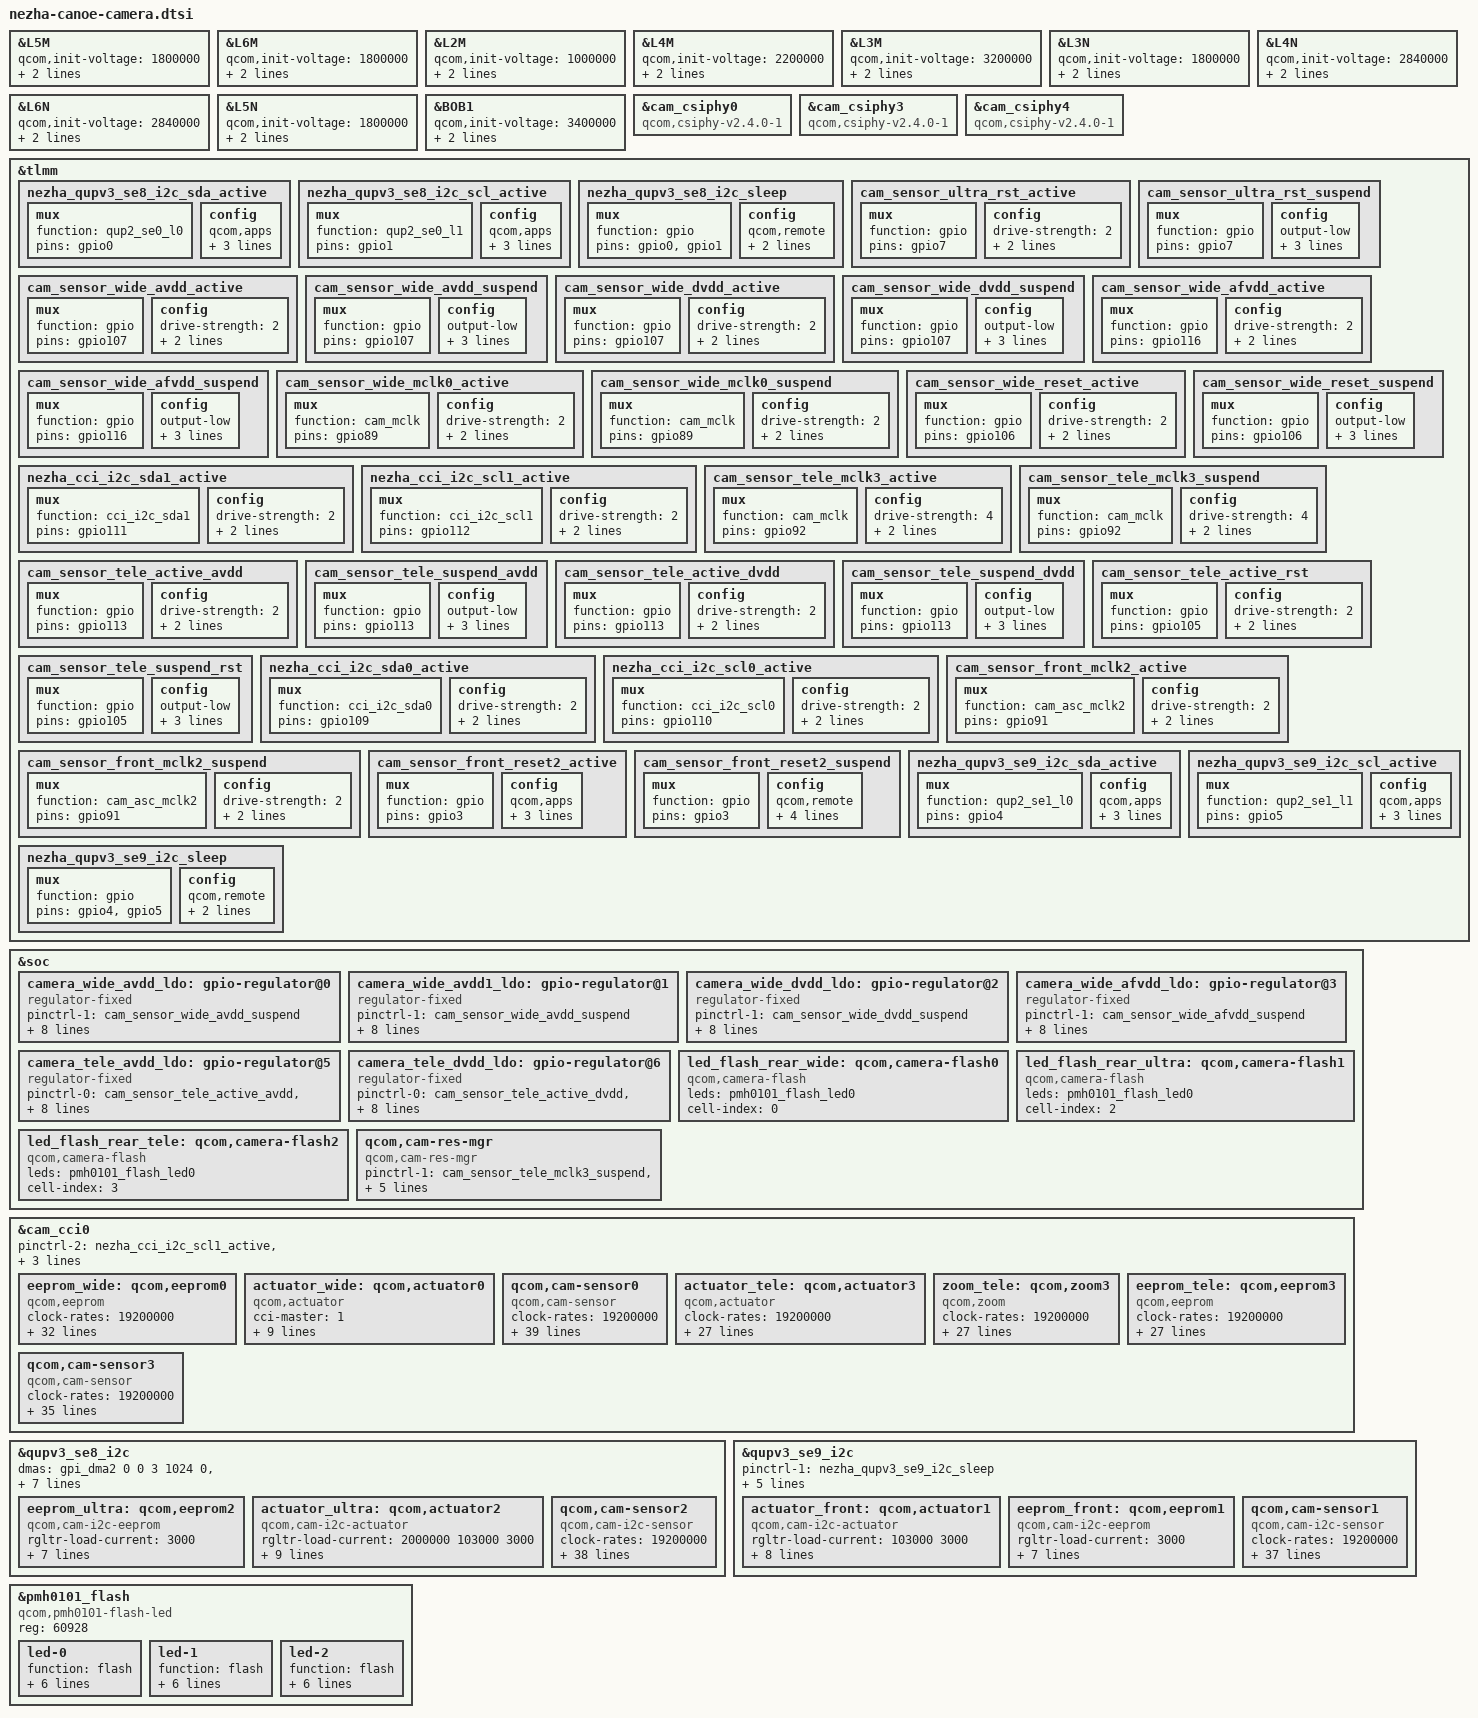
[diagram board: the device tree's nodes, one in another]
// SPDX-License-Identifier: GPL-2.0-only
/* Nezha OS4.0.7.0.XPACNXM board wiring, Canoe DTBO entry 1. */

&L5M {
	qcom,init-voltage = <1800000>;
	regulator-max-microvolt = <1800000>;
	regulator-min-microvolt = <1200000>;
};

&L6M {
	qcom,init-voltage = <1800000>;
	regulator-max-microvolt = <1800000>;
	regulator-min-microvolt = <1800000>;
};

&L2M {
	qcom,init-voltage = <1000000>;
	regulator-max-microvolt = <1000000>;
	regulator-min-microvolt = <1000000>;
};

&L4M {
	qcom,init-voltage = <2200000>;
	regulator-max-microvolt = <2200000>;
	regulator-min-microvolt = <2200000>;
};

&L3M {
	qcom,init-voltage = <3200000>;
	regulator-max-microvolt = <3200000>;
	regulator-min-microvolt = <3200000>;
};

&L3N {
	qcom,init-voltage = <1800000>;
	regulator-max-microvolt = <2800000>;
	regulator-min-microvolt = <1800000>;
};

&L4N {
	qcom,init-voltage = <2840000>;
	regulator-max-microvolt = <2840000>;
	regulator-min-microvolt = <2840000>;
};

&L6N {
	qcom,init-voltage = <2840000>;
	regulator-max-microvolt = <2840000>;
	regulator-min-microvolt = <2840000>;
};

&L5N {
	qcom,init-voltage = <1800000>;
	regulator-max-microvolt = <3304000>;
	regulator-min-microvolt = <1800000>;
};

&BOB1 {
	qcom,init-voltage = <3400000>;
	regulator-max-microvolt = <3400000>;
	regulator-min-microvolt = <3400000>;
};

&cam_csiphy0 {
	compatible = "qcom,csiphy-v2.4.0-1", "qcom,csiphy";
};

&cam_csiphy3 {
	compatible = "qcom,csiphy-v2.4.0-1", "qcom,csiphy";
};

&cam_csiphy4 {
	compatible = "qcom,csiphy-v2.4.0-1", "qcom,csiphy";
};

&tlmm {
	nezha_qupv3_se8_i2c_sda_active: nezha_qupv3_se8_i2c_sda_active {
		mux {
			function = "qup2_se0_l0";
			pins = "gpio0";
		};
		config {
			qcom,apps;
			bias-disable;
			drive-strength = <2>;
			pins = "gpio0";
		};
	};
	nezha_qupv3_se8_i2c_scl_active: nezha_qupv3_se8_i2c_scl_active {
		mux {
			function = "qup2_se0_l1";
			pins = "gpio1";
		};
		config {
			qcom,apps;
			bias-disable;
			drive-strength = <2>;
			pins = "gpio1";
		};
	};
	nezha_qupv3_se8_i2c_sleep: nezha_qupv3_se8_i2c_sleep {
		mux {
			function = "gpio";
			pins = "gpio0", "gpio1";
		};
		config {
			qcom,remote;
			drive-strength = <2>;
			pins = "gpio0", "gpio1";
		};
	};
	cam_sensor_ultra_rst_active: cam_sensor_ultra_rst_active {
		mux {
			function = "gpio";
			pins = "gpio7";
		};
		config {
			drive-strength = <2>;
			bias-disable;
			pins = "gpio7";
		};
	};
	cam_sensor_ultra_rst_suspend: cam_sensor_ultra_rst_suspend {
		mux {
			function = "gpio";
			pins = "gpio7";
		};
		config {
			output-low;
			drive-strength = <2>;
			bias-pull-down;
			pins = "gpio7";
		};
	};
	cam_sensor_wide_avdd_active: cam_sensor_wide_avdd_active {
		mux {
			function = "gpio";
			pins = "gpio107";
		};
		config {
			drive-strength = <2>;
			bias-disable;
			pins = "gpio107";
		};
	};
	cam_sensor_wide_avdd_suspend: cam_sensor_wide_avdd_suspend {
		mux {
			function = "gpio";
			pins = "gpio107";
		};
		config {
			output-low;
			drive-strength = <2>;
			bias-pull-down;
			pins = "gpio107";
		};
	};
	cam_sensor_wide_dvdd_active: cam_sensor_wide_dvdd_active {
		mux {
			function = "gpio";
			pins = "gpio107";
		};
		config {
			drive-strength = <2>;
			bias-disable;
			pins = "gpio107";
		};
	};
	cam_sensor_wide_dvdd_suspend: cam_sensor_wide_dvdd_suspend {
		mux {
			function = "gpio";
			pins = "gpio107";
		};
		config {
			output-low;
			drive-strength = <2>;
			bias-pull-down;
			pins = "gpio107";
		};
	};
	cam_sensor_wide_afvdd_active: cam_sensor_wide_afvdd_active {
		mux {
			function = "gpio";
			pins = "gpio116";
		};
		config {
			drive-strength = <2>;
			bias-disable;
			pins = "gpio116";
		};
	};
	cam_sensor_wide_afvdd_suspend: cam_sensor_wide_afvdd_suspend {
		mux {
			function = "gpio";
			pins = "gpio116";
		};
		config {
			output-low;
			drive-strength = <2>;
			bias-pull-down;
			pins = "gpio116";
		};
	};
	cam_sensor_wide_mclk0_active: cam_sensor_wide_mclk0_active {
		mux {
			function = "cam_mclk";
			pins = "gpio89";
		};
		config {
			drive-strength = <2>;
			bias-disable;
			pins = "gpio89";
		};
	};
	cam_sensor_wide_mclk0_suspend: cam_sensor_wide_mclk0_suspend {
		mux {
			function = "cam_mclk";
			pins = "gpio89";
		};
		config {
			drive-strength = <2>;
			bias-pull-down;
			pins = "gpio89";
		};
	};
	cam_sensor_wide_reset_active: cam_sensor_wide_reset_active {
		mux {
			function = "gpio";
			pins = "gpio106";
		};
		config {
			drive-strength = <2>;
			bias-disable;
			pins = "gpio106";
		};
	};
	cam_sensor_wide_reset_suspend: cam_sensor_wide_reset_suspend {
		mux {
			function = "gpio";
			pins = "gpio106";
		};
		config {
			output-low;
			drive-strength = <2>;
			bias-pull-down;
			pins = "gpio106";
		};
	};
	nezha_cci_i2c_sda1_active: nezha_cci_i2c_sda1_active {
		mux {
			function = "cci_i2c_sda1";
			pins = "gpio111";
		};
		config {
			drive-strength = <2>;
			bias-disable;
			pins = "gpio111";
		};
	};
	nezha_cci_i2c_scl1_active: nezha_cci_i2c_scl1_active {
		mux {
			function = "cci_i2c_scl1";
			pins = "gpio112";
		};
		config {
			drive-strength = <2>;
			bias-disable;
			pins = "gpio112";
		};
	};
	cam_sensor_tele_mclk3_active: cam_sensor_tele_mclk3_active {
		mux {
			function = "cam_mclk";
			pins = "gpio92";
		};
		config {
			drive-strength = <4>;
			bias-disable;
			pins = "gpio92";
		};
	};
	cam_sensor_tele_mclk3_suspend: cam_sensor_tele_mclk3_suspend {
		mux {
			function = "cam_mclk";
			pins = "gpio92";
		};
		config {
			drive-strength = <4>;
			bias-pull-down;
			pins = "gpio92";
		};
	};
	cam_sensor_tele_active_avdd: cam_sensor_tele_active_avdd {
		mux {
			function = "gpio";
			pins = "gpio113";
		};
		config {
			drive-strength = <2>;
			bias-disable;
			pins = "gpio113";
		};
	};
	cam_sensor_tele_suspend_avdd: cam_sensor_tele_suspend_avdd {
		mux {
			function = "gpio";
			pins = "gpio113";
		};
		config {
			output-low;
			drive-strength = <2>;
			bias-pull-down;
			pins = "gpio113";
		};
	};
	cam_sensor_tele_active_dvdd: cam_sensor_tele_active_dvdd {
		mux {
			function = "gpio";
			pins = "gpio113";
		};
		config {
			drive-strength = <2>;
			bias-disable;
			pins = "gpio113";
		};
	};
	cam_sensor_tele_suspend_dvdd: cam_sensor_tele_suspend_dvdd {
		mux {
			function = "gpio";
			pins = "gpio113";
		};
		config {
			output-low;
			drive-strength = <2>;
			bias-pull-down;
			pins = "gpio113";
		};
	};
	cam_sensor_tele_active_rst: cam_sensor_tele_active_rst {
		mux {
			function = "gpio";
			pins = "gpio105";
		};
		config {
			drive-strength = <2>;
			bias-disable;
			pins = "gpio105";
		};
	};
	cam_sensor_tele_suspend_rst: cam_sensor_tele_suspend_rst {
		mux {
			function = "gpio";
			pins = "gpio105";
		};
		config {
			output-low;
			drive-strength = <2>;
			bias-pull-down;
			pins = "gpio105";
		};
	};
	nezha_cci_i2c_sda0_active: nezha_cci_i2c_sda0_active {
		mux {
			function = "cci_i2c_sda0";
			pins = "gpio109";
		};
		config {
			drive-strength = <2>;
			bias-disable;
			pins = "gpio109";
		};
	};
	nezha_cci_i2c_scl0_active: nezha_cci_i2c_scl0_active {
		mux {
			function = "cci_i2c_scl0";
			pins = "gpio110";
		};
		config {
			drive-strength = <2>;
			bias-disable;
			pins = "gpio110";
		};
	};
	cam_sensor_front_mclk2_active: cam_sensor_front_mclk2_active {
		mux {
			function = "cam_asc_mclk2";
			pins = "gpio91";
		};
		config {
			drive-strength = <2>;
			bias-disable;
			pins = "gpio91";
		};
	};
	cam_sensor_front_mclk2_suspend: cam_sensor_front_mclk2_suspend {
		mux {
			function = "cam_asc_mclk2";
			pins = "gpio91";
		};
		config {
			drive-strength = <2>;
			bias-pull-down;
			pins = "gpio91";
		};
	};
	cam_sensor_front_reset2_active: cam_sensor_front_reset2_active {
		mux {
			function = "gpio";
			pins = "gpio3";
		};
		config {
			qcom,apps;
			drive-strength = <2>;
			bias-disable;
			pins = "gpio3";
		};
	};
	cam_sensor_front_reset2_suspend: cam_sensor_front_reset2_suspend {
		mux {
			function = "gpio";
			pins = "gpio3";
		};
		config {
			qcom,remote;
			output-low;
			drive-strength = <2>;
			bias-pull-down;
			pins = "gpio3";
		};
	};
	nezha_qupv3_se9_i2c_sda_active: nezha_qupv3_se9_i2c_sda_active {
		mux {
			function = "qup2_se1_l0";
			pins = "gpio4";
		};
		config {
			qcom,apps;
			bias-disable;
			drive-strength = <2>;
			pins = "gpio4";
		};
	};
	nezha_qupv3_se9_i2c_scl_active: nezha_qupv3_se9_i2c_scl_active {
		mux {
			function = "qup2_se1_l1";
			pins = "gpio5";
		};
		config {
			qcom,apps;
			bias-disable;
			drive-strength = <2>;
			pins = "gpio5";
		};
	};
	nezha_qupv3_se9_i2c_sleep: nezha_qupv3_se9_i2c_sleep {
		mux {
			function = "gpio";
			pins = "gpio4", "gpio5";
		};
		config {
			qcom,remote;
			drive-strength = <2>;
			pins = "gpio4", "gpio5";
		};
	};
};

&soc {
	camera_wide_avdd_ldo: gpio-regulator@0 {
		pinctrl-1 = <&cam_sensor_wide_avdd_suspend>;
		pinctrl-0 = <&cam_sensor_wide_avdd_active>;
		pinctrl-names = "wide_avdd_active", "wide_avdd_suspend";
		gpio = <&tlmm 107 0>;
		enable-active-high;
		regulator-enable-ramp-delay = <100>;
		regulator-max-microvolt = <2800000>;
		regulator-min-microvolt = <2800000>;
		regulator-name = "camera_wide_avdd_ldo";
		reg = <0 0>;
		compatible = "regulator-fixed";
	};
	camera_wide_avdd1_ldo: gpio-regulator@1 {
		pinctrl-1 = <&cam_sensor_wide_avdd_suspend>;
		pinctrl-0 = <&cam_sensor_wide_avdd_active>;
		pinctrl-names = "wide_avdd1_active", "wide_avdd1_suspend";
		gpio = <&tlmm 107 0>;
		enable-active-high;
		regulator-enable-ramp-delay = <100>;
		regulator-max-microvolt = <1800000>;
		regulator-min-microvolt = <1800000>;
		regulator-name = "camera_wide_avdd1_ldo";
		reg = <1 0>;
		compatible = "regulator-fixed";
	};
	camera_wide_dvdd_ldo: gpio-regulator@2 {
		pinctrl-1 = <&cam_sensor_wide_dvdd_suspend>;
		pinctrl-0 = <&cam_sensor_wide_dvdd_active>;
		pinctrl-names = "wide_dvdd_active", "wide_dvdd_suspend";
		gpio = <&tlmm 107 0>;
		enable-active-high;
		regulator-enable-ramp-delay = <100>;
		regulator-max-microvolt = <952000>;
		regulator-min-microvolt = <952000>;
		regulator-name = "camera_wide_dvdd_ldo";
		reg = <2 0>;
		compatible = "regulator-fixed";
	};
	camera_wide_afvdd_ldo: gpio-regulator@3 {
		pinctrl-1 = <&cam_sensor_wide_afvdd_suspend>;
		pinctrl-0 = <&cam_sensor_wide_afvdd_active>;
		pinctrl-names = "wide_afvdd_active", "wide_afvdd_suspend";
		gpio = <&tlmm 116 0>;
		enable-active-high;
		regulator-enable-ramp-delay = <100>;
		regulator-max-microvolt = <3304000>;
		regulator-min-microvolt = <3304000>;
		regulator-name = "camera_wide_afvdd_ldo";
		reg = <3 0>;
		compatible = "regulator-fixed";
	};
	camera_tele_avdd_ldo: gpio-regulator@5 {
		pinctrl-0 = <&cam_sensor_tele_active_avdd>,
			<&cam_sensor_tele_suspend_avdd>;
		pinctrl-names = "tele_avdd_active", "tele_avdd_suspend";
		gpio = <&tlmm 113 0>;
		enable-active-high;
		regulator-enable-ramp-delay = <100>;
		regulator-max-microvolt = <2200000>;
		regulator-min-microvolt = <2200000>;
		regulator-name = "camera_tele_avdd_ldo";
		reg = <5 0>;
		compatible = "regulator-fixed";
	};
	camera_tele_dvdd_ldo: gpio-regulator@6 {
		pinctrl-0 = <&cam_sensor_tele_active_dvdd>,
			<&cam_sensor_tele_suspend_dvdd>;
		pinctrl-names = "tele_avdd_active", "tele_avdd_suspend";
		gpio = <&tlmm 113 0>;
		enable-active-high;
		regulator-enable-ramp-delay = <100>;
		regulator-max-microvolt = <950000>;
		regulator-min-microvolt = <950000>;
		regulator-name = "camera_tele_dvdd_ldo";
		reg = <6 0>;
		compatible = "regulator-fixed";
	};
	led_flash_rear_wide: qcom,camera-flash0 {
		status = "ok";
		leds = <&pmh0101_flash_led0>;
		compatible = "qcom,camera-flash";
		cell-index = <0>;
	};
	led_flash_rear_ultra: qcom,camera-flash1 {
		status = "ok";
		leds = <&pmh0101_flash_led0>;
		compatible = "qcom,camera-flash";
		cell-index = <2>;
	};
	led_flash_rear_tele: qcom,camera-flash2 {
		status = "ok";
		leds = <&pmh0101_flash_led0>;
		compatible = "qcom,camera-flash";
		cell-index = <3>;
	};
	qcom,cam-res-mgr {
		status = "ok";
		pinctrl-1 = <&cam_sensor_tele_mclk3_suspend>,
			<&cam_sensor_tele_suspend_rst>;
		pinctrl-0 = <&cam_sensor_tele_mclk3_active>,
			<&cam_sensor_tele_active_rst>;
		pinctrl-names = "cam_tele_active", "cam_tele_suspend";
		shared-pctrl-gpio-names = "cam_tele", "cam_tele";
		/* Stock 604/617 assume TLMM base 512; use controller-relative pins. */
		shared-pinctrl-gpios = <&tlmm 92 0>, <&tlmm 105 0>;
		compatible = "qcom,cam-res-mgr";
	};
};

&cam_cci0 {
	pinctrl-2 = <&nezha_cci_i2c_scl1_active>,
		<&nezha_cci_i2c_sda1_active>;
	pinctrl-0 = <&nezha_cci_i2c_scl0_active>,
		<&nezha_cci_i2c_sda0_active>;
	eeprom_wide: qcom,eeprom0 {
		status = "ok";
		clock-rates = <19200000>;
		clock-cntl-level = "nominal";
		clock-names = "cam_clk";
		clocks = <&cambistmclkcc 2>;
		cci-master = <1>;
		gpio-req-tbl-label = "CAMIF_MCLK0", "CAMW_RESET";
		gpio-req-tbl-flags = <1 0>;
		gpio-req-tbl-num = <0 1>;
		gpio-reset = <1>;
		gpios = <&tlmm 89 0>,
			<&tlmm 106 0>;
		pinctrl-1 = <&cam_sensor_wide_mclk0_suspend>,
			<&cam_sensor_wide_reset_suspend>;
		pinctrl-0 = <&cam_sensor_wide_mclk0_active>,
			<&cam_sensor_wide_reset_active>;
		pinctrl-names = "cam_default", "cam_suspend";
		gpio-no-mux = <0>;
		rgltr-load-current = <150000 150000 150000 150000 2000000 2000000 150000>;
		rgltr-max-voltage = <2800000 1800000 1800000 952000 3296000 3400000 3304000>;
		rgltr-min-voltage = <2800000 1800000 1200000 952000 3296000 3400000 3304000>;
		rgltr-cntrl-support;
		regulator-names = "cam_vana", "cam_v_custom1", "cam_vio", "cam_vdig", "cam_bob2", "cam_bob", "cam_vaf";
		power-domains = <&camcc 5>;
		cam_bob2-supply = <&BOB2>;
		cam_bob-supply = <&BOB1>;
		cam_vaf-supply = <&camera_wide_afvdd_ldo>;
		cam_vdig-supply = <&camera_wide_dvdd_ldo>;
		cam_vio-supply = <&L5M>;
		cam_v_custom1-supply = <&camera_wide_avdd1_ldo>;
		cam_vana-supply = <&camera_wide_avdd_ldo>;
		compatible = "qcom,eeprom";
		cell-index = <0>;
	};
	actuator_wide: qcom,actuator0 {
		status = "ok";
		cci-master = <1>;
		rgltr-load-current = <2000000 150000 150000>;
		rgltr-max-voltage = <3400000 3304000 1800000>;
		rgltr-min-voltage = <3400000 3304000 1200000>;
		rgltr-cntrl-support;
		regulator-names = "cam_bob", "cam_vaf", "cam_vio";
		cam_vio-supply = <&L5M>;
		cam_vaf-supply = <&camera_wide_afvdd_ldo>;
		cam_bob-supply = <&BOB1>;
		compatible = "qcom,actuator";
		cell-index = <0>;
	};
	qcom,cam-sensor0 {
		status = "ok";
		clock-rates = <19200000>;
		clock-cntl-level = "nominal";
		clock-names = "cam_clk";
		clocks = <&cambistmclkcc 2>;
		cci-master = <1>;
		gpio-req-tbl-label = "CAMIF_MCLK0", "CAMW_RESET";
		gpio-req-tbl-flags = <1 0>;
		gpio-req-tbl-num = <0 1>;
		gpio-reset = <1>;
		gpios = <&tlmm 89 0>,
			<&tlmm 106 0>;
		pinctrl-1 = <&cam_sensor_wide_mclk0_suspend>,
			<&cam_sensor_wide_reset_suspend>;
		pinctrl-0 = <&cam_sensor_wide_mclk0_active>,
			<&cam_sensor_wide_reset_active>;
		pinctrl-names = "cam_default", "cam_suspend";
		gpio-no-mux = <0>;
		rgltr-load-current = <150000 150000 150000 150000 2000000 2000000 150000>;
		rgltr-max-voltage = <2800000 1800000 1800000 952000 3296000 3400000 3304000>;
		rgltr-min-voltage = <2800000 1800000 1200000 952000 3296000 3400000 3304000>;
		rgltr-cntrl-support;
		regulator-names = "cam_vana", "cam_v_custom1", "cam_vio", "cam_vdig", "cam_bob2", "cam_bob", "cam_vaf";
		power-domains = <&camcc 5>;
		cam_bob2-supply = <&BOB2>;
		cam_bob-supply = <&BOB1>;
		cam_vaf-supply = <&camera_wide_afvdd_ldo>;
		cam_vdig-supply = <&camera_wide_dvdd_ldo>;
		cam_vio-supply = <&L5M>;
		cam_v_custom1-supply = <&camera_wide_avdd1_ldo>;
		cam_vana-supply = <&camera_wide_avdd_ldo>;
		sensor-position-yaw = <180>;
		sensor-position-pitch = <0>;
		sensor-position-roll = <90>;
		led-flash-src = <&led_flash_rear_wide>;
		actuator-src = <&actuator_wide>;
		eeprom-src = <&eeprom_wide>;
		csiphy-sd-index = <0>;
		compatible = "qcom,cam-sensor";
		cell-index = <0>;
	};
	actuator_tele: qcom,actuator3 {
		status = "ok";
		clock-rates = <19200000>;
		clock-cntl-level = "nominal";
		clock-names = "cam_clk";
		clocks = <&cambistmclkcc 8>;
		cci-master = <0>;
		gpio-req-tbl-label = "CAMIF_MCLK3", "CAMW_RESET";
		gpio-req-tbl-flags = <1 0>;
		gpio-req-tbl-num = <0 1>;
		gpio-reset = <1>;
		gpios = <&tlmm 92 0>,
			<&tlmm 105 0>;
		use-shared-clk;
		gpio-no-mux = <0>;
		rgltr-load-current = <150000 150000 150000 2000000 150000 150000>;
		rgltr-max-voltage = <2200000 950000 1800000 3296000 3304000 2800000>;
		rgltr-min-voltage = <2200000 950000 1800000 3296000 1800000 1800000>;
		rgltr-cntrl-support;
		regulator-names = "cam_vana", "cam_vdig", "cam_vio", "cam_bob2", "cam_vaf", "cam_v_custom1";
		power-domains = <&camcc 5>;
		cam_v_custom1-supply = <&L3N>;
		cam_vaf-supply = <&L5N>;
		cam_bob2-supply = <&BOB2>;
		cam_vio-supply = <&L5M>;
		cam_vdig-supply = <&camera_tele_dvdd_ldo>;
		cam_vana-supply = <&camera_tele_avdd_ldo>;
		compatible = "qcom,actuator";
		cell-index = <3>;
	};
	zoom_tele: qcom,zoom3 {
		status = "ok";
		clock-rates = <19200000>;
		clock-cntl-level = "nominal";
		clock-names = "cam_clk";
		clocks = <&cambistmclkcc 8>;
		cci-master = <0>;
		gpio-req-tbl-label = "CAMIF_MCLK3", "CAMW_RESET";
		gpio-req-tbl-flags = <1 0>;
		gpio-req-tbl-num = <0 1>;
		gpio-reset = <1>;
		gpios = <&tlmm 92 0>,
			<&tlmm 105 0>;
		use-shared-clk;
		gpio-no-mux = <0>;
		rgltr-load-current = <150000 150000 150000 2000000 150000 150000>;
		rgltr-max-voltage = <2200000 950000 1800000 3296000 3304000 2800000>;
		rgltr-min-voltage = <2200000 950000 1800000 3296000 1800000 1800000>;
		rgltr-cntrl-support;
		regulator-names = "cam_vana", "cam_vdig", "cam_vio", "cam_bob2", "cam_vaf", "cam_v_custom1";
		power-domains = <&camcc 5>;
		cam_v_custom1-supply = <&L3N>;
		cam_vaf-supply = <&L5N>;
		cam_bob2-supply = <&BOB2>;
		cam_vio-supply = <&L5M>;
		cam_vdig-supply = <&camera_tele_dvdd_ldo>;
		cam_vana-supply = <&camera_tele_avdd_ldo>;
		compatible = "qcom,zoom";
		cell-index = <3>;
	};
	eeprom_tele: qcom,eeprom3 {
		status = "ok";
		clock-rates = <19200000>;
		clock-cntl-level = "nominal";
		clock-names = "cam_clk";
		clocks = <&cambistmclkcc 8>;
		cci-master = <0>;
		gpio-req-tbl-label = "CAMIF_MCLK3", "CAMW_RESET";
		gpio-req-tbl-flags = <1 0>;
		gpio-req-tbl-num = <0 1>;
		gpio-reset = <1>;
		gpios = <&tlmm 92 0>,
			<&tlmm 105 0>;
		use-shared-clk;
		gpio-no-mux = <0>;
		rgltr-load-current = <150000 150000 150000 2000000 150000 150000>;
		rgltr-max-voltage = <2200000 950000 1800000 3296000 3304000 2800000>;
		rgltr-min-voltage = <2200000 950000 1800000 3296000 1800000 1800000>;
		rgltr-cntrl-support;
		regulator-names = "cam_vana", "cam_vdig", "cam_vio", "cam_bob2", "cam_vaf", "cam_v_custom1";
		power-domains = <&camcc 5>;
		cam_v_custom1-supply = <&L3N>;
		cam_vaf-supply = <&L5N>;
		cam_bob2-supply = <&BOB2>;
		cam_vio-supply = <&L5M>;
		cam_vdig-supply = <&camera_tele_dvdd_ldo>;
		cam_vana-supply = <&camera_tele_avdd_ldo>;
		compatible = "qcom,eeprom";
		cell-index = <3>;
	};
	qcom,cam-sensor3 {
		status = "ok";
		clock-rates = <19200000>;
		clock-cntl-level = "nominal";
		clock-names = "cam_clk";
		clocks = <&cambistmclkcc 8>;
		cci-master = <0>;
		gpio-req-tbl-label = "CAMIF_MCLK3", "CAMW_RESET";
		gpio-req-tbl-flags = <1 0>;
		gpio-req-tbl-num = <0 1>;
		gpio-reset = <1>;
		gpios = <&tlmm 92 0>,
			<&tlmm 105 0>;
		use-shared-clk;
		gpio-no-mux = <0>;
		rgltr-load-current = <150000 150000 150000 2000000 150000 150000>;
		rgltr-max-voltage = <2200000 950000 1800000 3296000 3304000 2800000>;
		rgltr-min-voltage = <2200000 950000 1800000 3296000 1800000 1800000>;
		rgltr-cntrl-support;
		regulator-names = "cam_vana", "cam_vdig", "cam_vio", "cam_bob2", "cam_vaf", "cam_v_custom1";
		power-domains = <&camcc 5>;
		cam_v_custom1-supply = <&L3N>;
		cam_vaf-supply = <&L5N>;
		cam_bob2-supply = <&BOB2>;
		cam_vio-supply = <&L5M>;
		cam_vdig-supply = <&camera_tele_dvdd_ldo>;
		cam_vana-supply = <&camera_tele_avdd_ldo>;
		sensor-position-yaw = <180>;
		sensor-position-pitch = <0>;
		sensor-position-roll = <90>;
		led-flash-src = <&led_flash_rear_tele>;
		eeprom-src = <&eeprom_tele>;
		zoom-src = <&zoom_tele>;
		actuator-src = <&actuator_tele>;
		csiphy-sd-index = <3>;
		compatible = "qcom,cam-sensor";
		cell-index = <3>;
	};
};

&qupv3_se8_i2c {
	dmas = <&gpi_dma2 0 0 3 1024 0>,
		<&gpi_dma2 1 0 3 1024 0>;
	pinctrl-1 = <&nezha_qupv3_se8_i2c_sleep>;
	pinctrl-0 = <&nezha_qupv3_se8_i2c_sda_active>,
		<&nezha_qupv3_se8_i2c_scl_active>;
	qcom,pm-ctrl-client;
	qcom,clk-freq-out = <1000000>;
	qcom,high-perf;
	status = "ok";
	eeprom_ultra: qcom,eeprom2 {
		status = "ok";
		rgltr-load-current = <3000>;
		rgltr-max-voltage = <1800000>;
		rgltr-min-voltage = <1800000>;
		rgltr-cntrl-support;
		regulator-names = "cam_vio";
		cam_vio-supply = <&L5M>;
		compatible = "qcom,cam-i2c-eeprom";
		reg = <80>;
		cell-index = <2>;
	};
	actuator_ultra: qcom,actuator2 {
		status = "ok";
		rgltr-load-current = <2000000 103000 3000>;
		rgltr-max-voltage = <3296000 3200000 1800000>;
		rgltr-min-voltage = <3296000 3200000 1800000>;
		rgltr-cntrl-support;
		regulator-names = "cam_bob2", "cam_vaf", "cam_vio";
		cam_vio-supply = <&L5M>;
		cam_vaf-supply = <&L3M>;
		cam_bob2-supply = <&BOB2>;
		compatible = "qcom,cam-i2c-actuator";
		reg = <9>;
		cell-index = <2>;
	};
	qcom,cam-sensor2 {
		status = "ok";
		clock-rates = <19200000>;
		clock-cntl-level = "nominal";
		clock-names = "cam_clk";
		clocks = <&cambistmclkcc 10>;
		gpio-req-tbl-label = "CAMIF_MCLK4", "CAM_RESET4";
		gpio-req-tbl-flags = <1 0>;
		gpio-req-tbl-num = <0 1>;
		gpio-reset = <1>;
		gpios = <&tlmm 93 0>,
			<&tlmm 7 0>;
		pinctrl-1 = <&cam_sensor_mclk4_suspend>,
			<&cam_sensor_suspend_rst4>;
		pinctrl-0 = <&cam_sensor_mclk4_active>,
			<&cam_sensor_active_rst4>;
		pinctrl-names = "cam_default", "cam_suspend";
		gpio-no-mux = <0>;
		rgltr-load-current = <103000 522730 150000 103000 150000 2000000>;
		rgltr-max-voltage = <1800000 1000000 2200000 3200000 1800000 3296000>;
		rgltr-min-voltage = <1800000 1000000 2200000 3200000 1800000 3296000>;
		aon-camera-id = <0>;
		rgltr-cntrl-support;
		regulator-names = "cam_vio", "cam_vdig", "cam_vana", "cam_vaf", "cam_v_custom2", "cam_bob2";
		power-domains = <&camcc 5>;
		cam_bob2-supply = <&BOB2>;
		cam_v_custom2-supply = <&L6M>;
		cam_vaf-supply = <&L3M>;
		cam_vana-supply = <&L4M>;
		cam_vdig-supply = <&L2M>;
		cam_vio-supply = <&L5M>;
		sensor-position-yaw = <180>;
		sensor-position-pitch = <0>;
		sensor-position-roll = <90>;
		eeprom-src = <&eeprom_ultra>;
		actuator-src = <&actuator_ultra>;
		led-flash-src = <&led_flash_rear_ultra>;
		csiphy-sd-index = <4>;
		compatible = "qcom,cam-i2c-sensor";
		reg = <54>;
		cell-index = <2>;
	};
};

&qupv3_se9_i2c {
	pinctrl-1 = <&nezha_qupv3_se9_i2c_sleep>;
	pinctrl-0 = <&nezha_qupv3_se9_i2c_sda_active>,
		<&nezha_qupv3_se9_i2c_scl_active>;
	qcom,pm-ctrl-client;
	qcom,clk-freq-out = <1000000>;
	qcom,high-perf;
	status = "ok";
	actuator_front: qcom,actuator1 {
		rgltr-load-current = <103000 3000>;
		rgltr-max-voltage = <2840000 1800000>;
		rgltr-min-voltage = <2840000 1800000>;
		rgltr-cntrl-support;
		regulator-names = "cam_vaf", "cam_vio";
		cam_vio-supply = <&L5M>;
		cam_vaf-supply = <&L4N>;
		compatible = "qcom,cam-i2c-actuator";
		reg = <9>;
		cell-index = <1>;
	};
	eeprom_front: qcom,eeprom1 {
		status = "ok";
		rgltr-load-current = <3000>;
		rgltr-max-voltage = <1800000>;
		rgltr-min-voltage = <1800000>;
		rgltr-cntrl-support;
		regulator-names = "cam_vio";
		cam_vio-supply = <&L5M>;
		compatible = "qcom,cam-i2c-eeprom";
		reg = <81>;
		cell-index = <1>;
	};
	qcom,cam-sensor1 {
		status = "ok";
		clock-rates = <19200000>;
		clock-cntl-level = "nominal";
		clock-names = "cam_clk";
		clocks = <&cambistmclkcc 6>;
		gpio-req-tbl-label = "CAMIF_MCLK2", "CAM_RESET2";
		gpio-req-tbl-flags = <1 0>;
		gpio-req-tbl-num = <0 1>;
		gpio-reset = <1>;
		gpios = <&tlmm 91 0>,
			<&tlmm 3 0>;
		pinctrl-1 = <&cam_sensor_front_mclk2_suspend>,
			<&cam_sensor_front_reset2_suspend>;
		pinctrl-0 = <&cam_sensor_front_mclk2_active>,
			<&cam_sensor_front_reset2_active>;
		pinctrl-names = "cam_default", "cam_suspend";
		gpio-no-mux = <0>;
		rgltr-load-current = <3000 283000 50000 103000 2000000 2000000>;
		rgltr-max-voltage = <1800000 1160000 2840000 2840000 3400000 3296000>;
		rgltr-min-voltage = <1800000 1160000 2840000 2840000 3400000 3296000>;
		regulator-names = "cam_vio", "cam_vdig", "cam_vana", "cam_vaf", "cam_bob", "cam_bob2";
		aon-camera-id = <1>;
		rgltr-cntrl-support;
		power-domains = <&camcc 5>;
		cam_bob2-supply = <&BOB2>;
		cam_bob-supply = <&BOB1>;
		cam_vaf-supply = <&L4N>;
		cam_vana-supply = <&L6N>;
		cam_vdig-supply = <&L1N>;
		cam_vio-supply = <&L5M>;
		sensor-position-yaw = <0>;
		sensor-position-pitch = <0>;
		sensor-position-roll = <270>;
		csiphy-sd-index = <2>;
		eeprom-src = <&eeprom_front>;
		actuator-src = <&actuator_front>;
		compatible = "qcom,cam-i2c-sensor";
		reg = <16>;
		cell-index = <1>;
	};
};

&pmh0101_flash {
	compatible = "qcom,pmh0101-flash-led", "qcom,spmi-flash-led";
	reg = <60928>;
	led-0 {
		function = "flash";
		function-enumerator = <0>;
		color = <6>;
		led-sources = <1 4>;
		led-max-microamp = <500000>;
		flash-max-microamp = <1200000>;
		flash-max-timeout-us = <300000>;
	};
	led-1 {
		function = "flash";
		function-enumerator = <1>;
		color = <0>;
		led-sources = <2 3>;
		led-max-microamp = <500000>;
		flash-max-microamp = <2000000>;
		flash-max-timeout-us = <1280000>;
	};
	led-2 {
		function = "flash";
		function-enumerator = <2>;
		color = <4>;
		led-sources = <1 2 3 4>;
		led-max-microamp = <500000>;
		flash-max-microamp = <2000000>;
		flash-max-timeout-us = <1280000>;
	};
};
